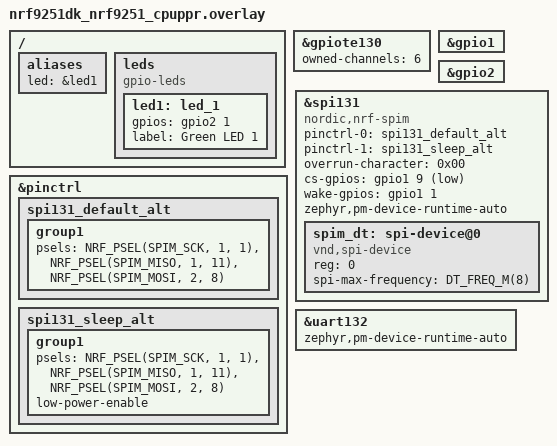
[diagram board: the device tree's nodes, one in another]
/*
 * Copyright (c) 2026 Nordic Semiconductor ASA
 *
 * SPDX-License-Identifier: LicenseRef-Nordic-5-Clause
 */

/* Test requires following loopbacks:
 * SCK:  P1.00 - P1.01
 * MISO: P1.04 - P1.11
 * MOSI: P2.06 - P2.08
 * CS:   P1.08 - P1.09 (connected with antena)
 * WAKE: P1.00 - P1.01
 */

/ {
	aliases {
		led = &led1;
	};

	leds {
		compatible = "gpio-leds";

		led1: led_1 {
			gpios = <&gpio2 1 GPIO_ACTIVE_HIGH>;
			label = "Green LED 1";
		};
	};
};

&gpiote130 {
	status = "okay";
	owned-channels = <6>;
};

&gpio1 {
	status = "okay";
};

&gpio2 {
	status = "okay";
};

&pinctrl {
	spi131_default_alt: spi131_default_alt {
		group1 {
			psels = <NRF_PSEL(SPIM_SCK, 1, 1)>,
				<NRF_PSEL(SPIM_MISO, 1, 11)>,
				<NRF_PSEL(SPIM_MOSI, 2, 8)>;
		};
	};

	spi131_sleep_alt: spi131_sleep_alt {
		group1 {
			psels = <NRF_PSEL(SPIM_SCK, 1, 1)>,
				<NRF_PSEL(SPIM_MISO, 1, 11)>,
				<NRF_PSEL(SPIM_MOSI, 2, 8)>;
			low-power-enable;
		};
	};
};

&spi131 {
	compatible = "nordic,nrf-spim";
	status = "okay";
	pinctrl-0 = <&spi131_default_alt>;
	pinctrl-1 = <&spi131_sleep_alt>;
	pinctrl-names = "default", "sleep";
	overrun-character = <0x00>;
	cs-gpios = <&gpio1 9 GPIO_ACTIVE_LOW>;
	wake-gpios = <&gpio1 1 GPIO_ACTIVE_HIGH>;
	zephyr,pm-device-runtime-auto;

	spim_dt: spi-device@0 {
		compatible = "vnd,spi-device";
		reg = <0>;
		spi-max-frequency = <DT_FREQ_M(8)>;
	};
};

&uart132 {
	zephyr,pm-device-runtime-auto;
};
